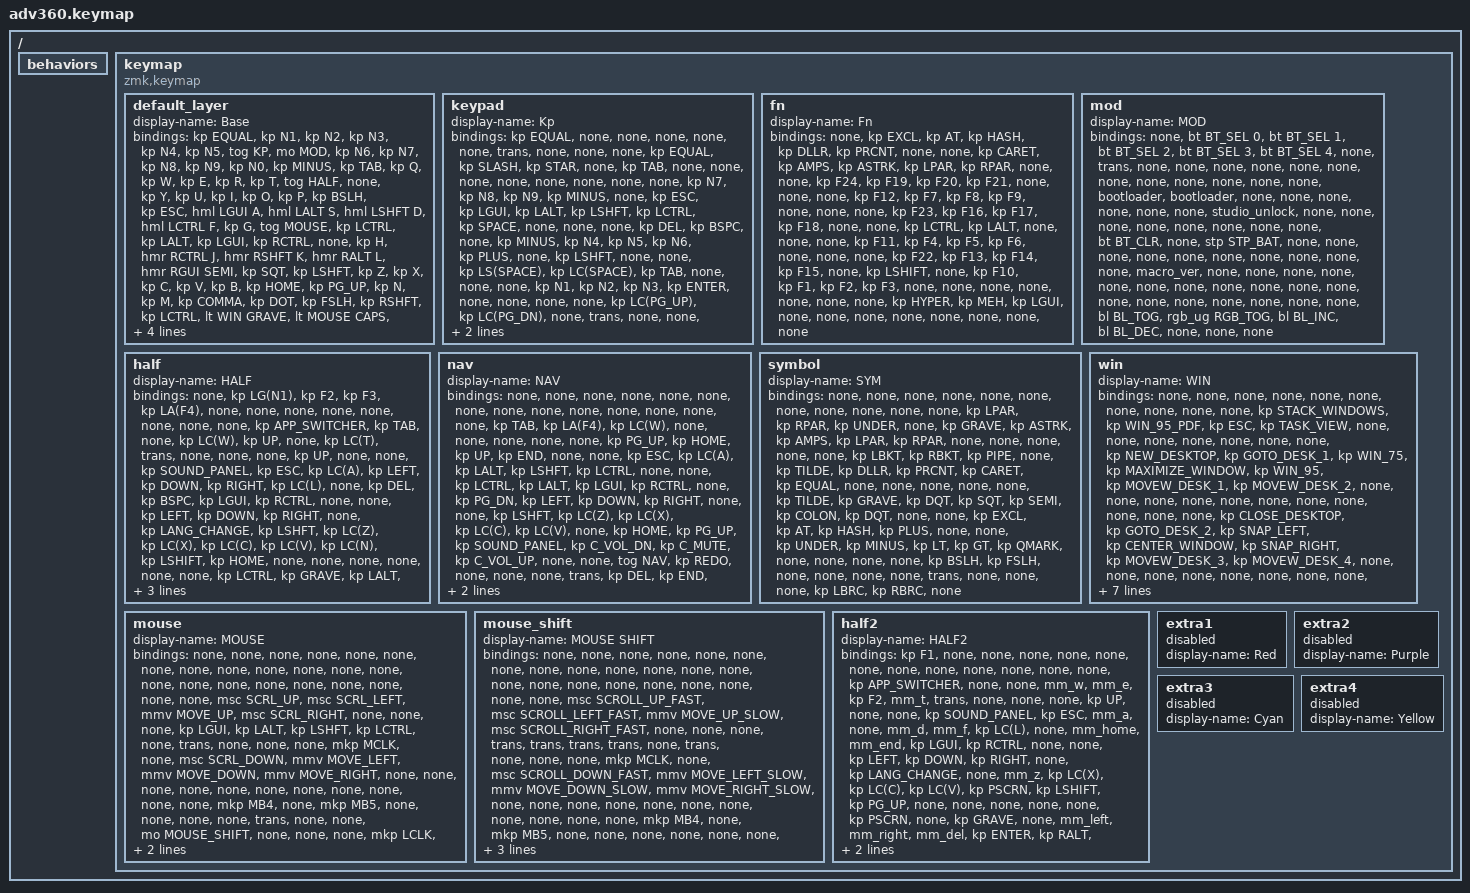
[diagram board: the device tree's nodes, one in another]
// Keep mouse.h first: it overrides ZMK pointing defaults before
// behaviors.dtsi or any other include can pull in pointing.h.
#include "mouse.h"

#include <behaviors.dtsi>
#include <dt-bindings/zmk/keys.h>
#include <dt-bindings/zmk/bt.h>
#include <dt-bindings/zmk/rgb.h>
#include <dt-bindings/zmk/stp.h>
#include <dt-bindings/zmk/backlight.h>

#include "mouse.dtsi"
#include "macropad.dtsi"
#include "homerow_mods.dtsi"

#ifndef KEYMAP_DRAWER
#include "win_mgmt.h"
#define SOUND_PANEL LC(LG(V))
#define LANG_CHANGE LA(LSHFT)
#define APP_SWITCHER LC(LA(TAB))

// Hyper = Left Control + Shift + LAlt + Winkey
#define HYPER LC(LS(LA(LGUI)))
// Meh = Left Control + Shift + LAlt
#define MEH   LC(LS(LALT))

// Win: Ctrl+Y or Ctrl+Shift+Z
// Mac: Command + Shift + Z
#define REDO LC(LS(Z))

#endif

#define BASE 0
#define KP   1
#define FN   2
#define MOD  3
#define HALF 4
#define NAV  5
#define SYM  6
#define WIN  7
#define MOUSE 8
#define MOUSE_SHIFT 9
#define HALF2 10


// mac screenshot
#define _SCRNS &kp LG(LS(NUMBER_4))

/ {
    behaviors {
      #include "macros.dtsi"
      #include "macros2.dtsi"
      #include "version.dtsi"
    };

  keymap {
    compatible = "zmk,keymap";

    default_layer {
      display-name = "Base";
      bindings = <
        &kp EQUAL  &kp N1          &kp N2          &kp N3          &kp N4          &kp N5 &tog KP                                                                                       &mo MOD  &kp N6       &kp N7        &kp N8          &kp N9          &kp N0          &kp MINUS
        &kp TAB    &kp Q           &kp W           &kp E           &kp R           &kp T  &tog HALF                                                                                     &none    &kp Y        &kp U         &kp I           &kp O           &kp P           &kp BSLH
        &kp ESC    &hml LGUI A     &hml LALT S     &hml LSHFT D    &hml LCTRL F    &kp G  &tog MOUSE                &kp LCTRL         &kp LALT     &kp LGUI  &kp RCTRL                  &none    &kp H        &hmr RCTRL J  &hmr RSHFT K    &hmr RALT L     &hmr RGUI SEMI  &kp SQT
        &kp LSHFT  &kp Z           &kp X           &kp C           &kp V           &kp B                                              &kp HOME     &kp PG_UP                                     &kp N        &kp M         &kp COMMA       &kp DOT         &kp FSLH        &kp RSHFT
        &kp LCTRL  &lt WIN GRAVE   &lt MOUSE CAPS  &kp LEFT        &kp RIGHT                          &lt NAV SPACE &lt KP DEL        &kp END      &kp PG_DN &lt FN ENTER &lt SYM BSPC                        &kp DOWN      &kp UP          &kp LBKT        &kp RBKT        &kp PRINTSCREEN
      >;
    };


    keypad {
      display-name = "Kp";
      bindings = <
        &kp EQUAL &none     &none     &none          &none           &none      &trans                                                         &none    &none      &none        &kp EQUAL   &kp SLASH   &kp STAR    &none
        &kp TAB   &none     &none     &none          &none           &none      &none                                                          &none    &none      &kp N7       &kp N8      &kp N9      &kp MINUS   &none
        &kp ESC   &kp LGUI  &kp LALT  &kp LSHFT      &kp LCTRL       &kp SPACE  &none           &none   &none   &kp DEL &kp BSPC               &none    &kp MINUS  &kp N4       &kp N5      &kp N6      &kp PLUS    &none
        &kp LSHFT &none     &none     &kp LS(SPACE)  &kp LC(SPACE)   &kp TAB                            &none   &none                                   &none      &kp N1       &kp N2      &kp N3      &kp ENTER   &none
        &none     &none     &none     &kp LC(PG_UP)  &kp LC(PG_DN)                        &none &trans  &none   &none   &kp ENTER &kp N0                           &macro_000   &kp COMMA   &kp DOT     &none       &kp PRINTSCREEN
      >;
    };


    fn {
      display-name = "Fn";
      bindings = <
        &none  &kp EXCL &kp AT   &kp HASH  &kp DLLR  &kp PRCNT &none                                                                 &none     &kp CARET &kp AMPS &kp ASTRK &kp LPAR  &kp RPAR &none
        &none  &kp F24  &kp F19  &kp F20   &kp F21   &none     &none                                                                 &none     &kp F12   &kp F7   &kp F8    &kp F9    &none    &none
        &none  &kp F23  &kp F16  &kp F17   &kp F18   &none     &none                   &kp LCTRL  &kp LALT    &none &none            &none     &kp F11   &kp F4   &kp F5    &kp F6    &none    &none
        &none  &kp F22  &kp F13  &kp F14   &kp F15   &none                                        &kp LSHIFT  &none                            &kp F10   &kp F1   &kp F2    &kp F3    &none    &none
        &none  &none    &none    &none     &none                             &kp HYPER &kp MEH    &kp LGUI    &none &none &none                          &none    &none     &none     &none    &none
      >;
    };



    mod {
      display-name = "MOD";
      bindings = <
        &none              &bt BT_SEL 0 &bt BT_SEL 1 &bt BT_SEL 2 &bt BT_SEL 3 &bt BT_SEL 4 &none                                                                            &trans                 &none        &none        &none        &none &none &none
        &none              &none        &none        &none        &none        &none        &bootloader                                                                      &bootloader            &none        &none        &none        &none &none &none
        &studio_unlock     &none        &none        &none        &none        &none        &none                   &none &none    &bt BT_CLR &none                          &stp STP_BAT           &none        &none        &none        &none &none &none
        &none              &none        &none        &none        &macro_ver   &none                                      &none    &none                                                            &none        &none        &none        &none &none &none
        &none              &none        &none        &none        &none                                       &none &none &none    &none      &bl BL_TOG &rgb_ug RGB_TOG                                         &bl BL_INC   &bl BL_DEC   &none &none &none
      >;
    };


    half {
      display-name = "HALF";
      bindings = <
        &none            &kp LG(N1)     &kp F2      &kp F3          &kp LA(F4)     &none      &none                                                                             &none  &none  &none       &none     &none     &none &kp APP_SWITCHER
        &kp TAB          &none          &kp LC(W)   &kp UP          &none          &kp LC(T)  &trans                                                                            &none  &none  &none       &kp UP    &none     &none &kp SOUND_PANEL
        &kp ESC          &kp LC(A)      &kp LEFT    &kp DOWN        &kp RIGHT      &kp LC(L)  &none                    &kp DEL     &kp BSPC     &kp LGUI  &kp RCTRL             &none  &none  &kp LEFT    &kp DOWN  &kp RIGHT &none &kp LANG_CHANGE
        &kp LSHFT        &kp LC(Z)      &kp LC(X)   &kp LC(C)       &kp LC(V)      &kp LC(N)                                       &kp LSHIFT   &kp HOME                               &none  &none       &none     &none     &none &none
        &kp LCTRL        &kp GRAVE      &kp LALT    &kp PG_UP       &kp PG_DN                             &kp SPACE    &kp ENTER   &kp LCTRL    &kp END   &kp ENTER &none                     &none       &none     &none     &none &kp PSCRN
      >;
    };


    nav {
      display-name = "NAV";
      bindings = <
        &none      &none           &none           &none       &none       &none   &none                                                                              &none  &none            &none         &none       &none         &none &none
        &kp TAB    &kp LA(F4)      &kp LC(W)       &none       &none       &none   &none                                                                              &none  &kp PG_UP        &kp HOME      &kp UP      &kp END       &none &none
        &kp ESC    &kp LC(A)       &kp LALT        &kp LSHFT   &kp LCTRL   &none   &none                        &kp LCTRL &kp LALT    &kp LGUI  &kp RCTRL             &none  &kp PG_DN        &kp LEFT      &kp DOWN    &kp RIGHT     &none &none
        &kp LSHFT  &kp LC(Z)       &kp LC(X)       &kp LC(C)   &kp LC(V)   &none                                          &kp HOME    &kp PG_UP                              &kp SOUND_PANEL  &kp C_VOL_DN  &kp C_MUTE  &kp C_VOL_UP  &none &none
        &tog NAV   &kp REDO        &none           &none       &none                                    &trans  &kp DEL   &kp END     &kp PG_DN &kp ENTER &kp BSPC                            &kp C_PREV    &kp C_PP    &kp C_NEXT    &none &none
      >;
    };


    symbol {
      display-name = "SYM";
      bindings = <
        &none       &none       &none       &none       &none       &none       &none                                             &none       &none       &none       &none       &kp LPAR    &kp RPAR    &kp UNDER
        &none       &kp GRAVE   &kp ASTRK   &kp AMPS    &kp LPAR    &kp RPAR    &none                                             &none       &none       &none       &none       &kp LBKT    &kp RBKT    &kp PIPE
        &none       &kp TILDE   &kp DLLR    &kp PRCNT   &kp CARET   &kp EQUAL   &none          &none &none    &none &none         &kp TILDE   &kp GRAVE   &kp DQT     &kp SQT     &kp SEMI    &kp COLON   &kp DQT
        &none       &none       &kp EXCL    &kp AT      &kp HASH    &kp PLUS                         &none    &none                           &kp UNDER   &kp MINUS   &kp LT      &kp GT      &kp QMARK   &none
        &none       &none       &none       &kp BSLH    &kp FSLH                         &none &none &none    &none &trans &none                          &none       &none       &kp LBRC    &kp RBRC    &none
      >;
    };


    win {
      display-name = "WIN";
      bindings = <
        &none   &none   &none  &none  &none &none &none                                                &none              &none            &none                 &kp STACK_WINDOWS       &kp WIN_95_PDF        &kp ESC            &kp TASK_VIEW
        &none   &none   &none  &none  &none &none &none                                                &kp NEW_DESKTOP    &kp GOTO_DESK_1  &kp WIN_75            &kp MAXIMIZE_WINDOW     &kp WIN_95            &kp MOVEW_DESK_1   &kp MOVEW_DESK_2
        &none   &none   &none  &none  &none &none &none            &none &none    &none  &none         &kp CLOSE_DESKTOP  &kp GOTO_DESK_2  &kp SNAP_LEFT         &kp CENTER_WINDOW       &kp SNAP_RIGHT        &kp MOVEW_DESK_3   &kp MOVEW_DESK_4
        &none   &none   &none  &none  &none &none                        &none    &none                                   &kp GOTO_DESK_3  &kp GOTO_DESK_LEFT    &kp MIN_RESTORE_WINDOW  &kp GOTO_DESK_RIGHT   &none              &kp TOG_WIN_PIN
        &none   &trans  &none  &none  &none                  &none &none &none    &none &none &none                                        &kp MOVEW_DESK_LEFT   &kp MOVEW_NEXT_MONITOR  &kp MOVEW_DESK_RIGHT  &none              &kp TOG_APP_PIN
      >;
    };


    mouse {
      display-name = "MOUSE";
      bindings = <
        &none   &none     &none     &none     &none      &none     &none                                                                 &none  &none             &none            &none            &none              &none &none
        &none   &none     &none     &none     &none      &none     &none                                                                 &none  &msc SCRL_UP      &msc SCRL_LEFT   &mmv MOVE_UP     &msc SCRL_RIGHT    &none &none
        &none   &kp LGUI  &kp LALT  &kp LSHFT &kp LCTRL  &none     &trans             &none &none    &none  &mkp MCLK                    &none  &msc SCRL_DOWN    &mmv MOVE_LEFT   &mmv MOVE_DOWN   &mmv MOVE_RIGHT    &none &none
        &none   &none     &none     &none     &none      &none                              &none    &none                                      &none             &mkp MB4         &none            &mkp MB5           &none &none
        &none   &none     &trans    &none     &none                         &mo MOUSE_SHIFT &none    &none  &none &mkp LCLK &mkp RCLK                             &none            &none            &none              &none &kp PRINTSCREEN
      >;
    };

    mouse_shift {
      display-name = "MOUSE SHIFT";
      bindings = <
        &none   &none   &none   &none   &none  &none &none                                                               &none  &none                   &none                   &none                 &none                   &none &none
        &none   &none   &none   &none   &none  &none &none                                                               &none  &msc SCROLL_UP_FAST     &msc SCROLL_LEFT_FAST   &mmv MOVE_UP_SLOW     &msc SCROLL_RIGHT_FAST  &none &none
        &none   &trans  &trans  &trans  &trans &none &trans           &none &none    &none  &mkp MCLK                    &none  &msc SCROLL_DOWN_FAST   &mmv MOVE_LEFT_SLOW     &mmv MOVE_DOWN_SLOW   &mmv MOVE_RIGHT_SLOW    &none &none
        &none   &none   &none   &none   &none  &none                        &none    &none                                      &none                   &mkp MB4                &none                 &mkp MB5                &none &none
        &none   &none   &none   &none   &none              &mo MOUSE_SHIFT &none    &none  &none &mkp LCLK &mkp RCLK                                   &none                   &none                 &none                   &none &trans
      >;
    };


    half2 {
      display-name = "HALF2";
      bindings = <
        &kp F1           &none      &none            &none      &none      &none      &none                                                                             &none  &none  &none       &none     &none     &none &kp APP_SWITCHER
        &none            &none      &mm_w            &mm_e      &kp F2     &mm_t      &trans                                                                            &none  &none  &none       &kp UP    &none     &none &kp SOUND_PANEL
        &kp ESC          &mm_a      &none            &mm_d      &mm_f      &kp LC(L)  &none                    &mm_home    &mm_end      &kp LGUI  &kp RCTRL             &none  &none  &kp LEFT    &kp DOWN  &kp RIGHT &none &kp LANG_CHANGE
        &none            &mm_z      &kp LC(X)        &kp LC(C)  &kp LC(V)  &kp PSCRN                                       &kp LSHIFT   &kp PG_UP                              &none  &none       &none     &none     &none &kp PSCRN
        &none            &kp GRAVE  &none            &mm_left   &mm_right                             &mm_del  &kp ENTER   &kp RALT     &kp PG_DN &kp ENTER &none                     &none       &none     &none     &none &none
      >;
    };

    extra1 {
      display-name = "Red";
      status = "reserved";
    };

    extra2 {
      display-name = "Purple";
      status = "reserved";
    };

    extra3 {
      display-name = "Cyan";
      status = "reserved";
    };

    extra4 {
      display-name = "Yellow";
      status = "reserved";
    };
  };
};
